AUTOSAR XML (schema 4-2-2)
package /MemSWC
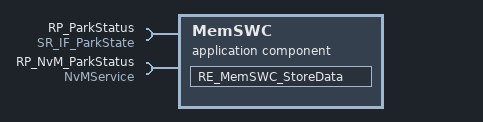
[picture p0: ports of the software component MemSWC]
  application sw component type MemSWC
    require port RP_ParkStatus: required-interface=SR_IF_ParkState
    require port RP_NvM_ParkStatus: required-interface=NvMService
    behavior SwcInternalBehavior: data-type-mapping=DataTypeMappingSet
      data received event DRE_RE_MemSWC_StoreData: start-on-event=RE_MemSWC_StoreData, data=RP_ParkStatus.DE_ParkState
      per instance memory ParkStatus: init-value=0, implementation-data-type=boolean, type=parkStatus, type-definition=boolean
      runnable RE_MemSWC_StoreData
        data-receive-point-by-arguments:
          access DRPA_DE_ParkState_0: accessed-variable=RP_ParkStatus.DE_ParkState
        sync call SynchronousServerCallPoint_0: operation=RP_NvM_ParkStatus.ReadBlock
        sync call SynchronousServerCallPoint_1: operation=RP_NvM_ParkStatus.SetRamBlockStatus
        sync call SynchronousServerCallPoint_2: operation=RP_NvM_ParkStatus.WriteBlock
      swc service dependency Srv_NvM_0: category=NV_BLOCK_COMPONENT, assigned-datas=role-based-data-assignment={role=ramBlock, used-pim=ParkStatus}
        service-needs:
          nv block needs NvM_Needs_0: restore-at-start=true, store-at-shutdown=true
